VERSION "1.1"

NS_ :

BS_:

BU_: Host

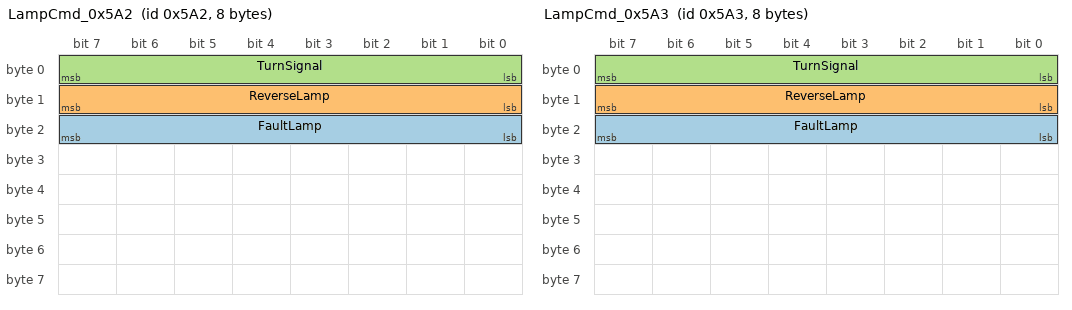
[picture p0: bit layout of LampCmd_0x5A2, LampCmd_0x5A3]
BO_ 1442 LampCmd_0x5A2: 8 Host
 SG_ FaultLamp : 23|8@0+ (1,0) [0|0] "" Vector__XXX
 SG_ ReverseLamp : 15|8@0+ (1,0) [0|0] "" Vector__XXX
 SG_ TurnSignal : 7|8@0+ (1.0,0) [0|0] "" Vector__XXX

BO_ 1443 LampCmd_0x5A3: 8 Host
 SG_ FaultLamp : 23|8@0+ (1,0) [0|0] "" Vector__XXX
 SG_ ReverseLamp : 15|8@0+ (1,0) [0|0] "" Vector__XXX
 SG_ TurnSignal : 7|8@0+ (1.0,0) [0|0] "" Vector__XXX

CM_ BO_ 1442 "Reference-driver layout";
CM_ BO_ 1443 "Protocol-document layout";

VAL_ 1442 TurnSignal 0 "off" 1 "left" 2 "right" ;
VAL_ 1443 TurnSignal 0 "off" 1 "left" 2 "right" ;
